# nrf54l15_application register map
Vendor: Nordic Semiconductor; Series: nrf54l; File version: 1
CPU: CM33 r0p4, little endian, MPU, FPU, 3 interrupt priority bits, 270 interrupts, 4 SAU regions
Registers are 32-bit, read-write, reset 0x0 unless marked. A register's access mark holds for its fields unless they carry their own. Offsets are from the block's base; [hi:lo] are bit positions; {n}, {i} and the like mark numbered series; 'fields as' and 'values as' point back to an identical list.

## GLOBAL_TEMP_NS — Temperature Sensor 0
Base 0x400D7000
Same registers: GLOBAL_TEMP_S 0x500D7000
0x00 TASKS_START wo — Start temperature measurement
  [0] TASKS_START
    1=Trigger task
0x04 TASKS_STOP wo — Stop temperature measurement
  [0] TASKS_STOP
    1=Trigger task
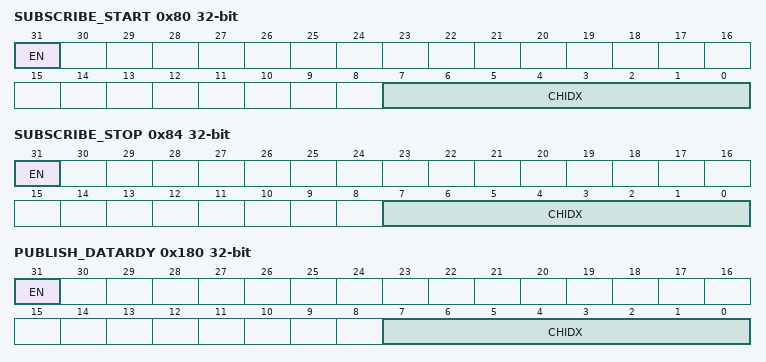
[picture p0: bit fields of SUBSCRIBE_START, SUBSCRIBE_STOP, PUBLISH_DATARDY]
0x80 SUBSCRIBE_START — Subscribe configuration for task START
  [31] EN
    0=Disabled (Disable subscription); 1=Enabled (Enable subscription)
  [7:0] CHIDX — DPPI channel that task START will subscribe to
0x84 SUBSCRIBE_STOP — Subscribe configuration for task STOP
  [31] EN
    values as SUBSCRIBE_START.EN
  [7:0] CHIDX — DPPI channel that task STOP will subscribe to
0x100 EVENTS_DATARDY — Temperature measurement complete, data ready
  [0] EVENTS_DATARDY
    0=NotGenerated (Event not generated); 1=Generated (Event generated)
0x180 PUBLISH_DATARDY — Publish configuration for event DATARDY
  [31] EN
    0=Disabled (Disable publishing); 1=Enabled (Enable publishing)
  [7:0] CHIDX — DPPI channel that event DATARDY will publish to
0x304 INTENSET — Enable interrupt
  [0] DATARDY write-1-sets — Write '1' to enable interrupt for event DATARDY
    on read: 0=Disabled (Read: Disabled); 1=Enabled (Read: Enabled) | on write: 1=Set (Enable)
0x308 INTENCLR — Disable interrupt
  [0] DATARDY write-1-clears — Write '1' to disable interrupt for event DATARDY
    on read: 0=Disabled (Read: Disabled); 1=Enabled (Read: Enabled) | on write: 1=Clear (Disable)
0x508 TEMP ro — Temperature in degC (0.25deg steps)
0x520 A0 reset 0x38C — Slope of 1st piece wise linear function
  [11:0] A0
0x524 A1 reset 0x3B3 — Slope of 2nd piece wise linear function
  [11:0] A1
0x528 A2 reset 0x3FA — Slope of 3rd piece wise linear function
  [11:0] A2
0x52C A3 reset 0x451 — Slope of 4th piece wise linear function
  [11:0] A3
0x530 A4 reset 0x4AA — Slope of 5th piece wise linear function
  [11:0] A4
0x534 A5 reset 0x539 — Slope of 6th piece wise linear function
  [11:0] A5
0x538 A6 reset 0x578 — Slope of 7th piece wise linear function
  [11:0] A6
0x540 B0 reset 0x37 — y-intercept of 1st piece wise linear function
  [11:0] B0
0x544 B1 reset 0x11 — y-intercept of 2nd piece wise linear function
  [11:0] B1
0x548 B2 reset 0x5 — y-intercept of 3rd piece wise linear function
  [11:0] B2
0x54C B3 reset 0x2B — y-intercept of 4th piece wise linear function
  [11:0] B3
0x550 B4 reset 0x8F — y-intercept of 5th piece wise linear function
  [11:0] B4
0x554 B5 reset 0x15D — y-intercept of 6th piece wise linear function
  [11:0] B5
0x558 B6 reset 0x1C0 — y-intercept of 7th piece wise linear function
  [11:0] B6
0x560 T0 reset 0xE5 — End point of 1st piece wise linear function
  [7:0] T0
0x564 T1 reset 0xFB — End point of 2nd piece wise linear function
  [7:0] T1
0x568 T2 reset 0x10 — End point of 3rd piece wise linear function
  [7:0] T2
0x56C T3 reset 0x2B — End point of 4th piece wise linear function
  [7:0] T3
0x570 T4 reset 0x41 — End point of 5th piece wise linear function
  [7:0] T4
0x574 T5 reset 0x50 — End point of 6th piece wise linear function
  [7:0] T5

## GLOBAL_POWER_NS — Power control 0
Base 0x4010E000; alternate view of GLOBAL_CLOCK_NS
Same registers: GLOBAL_POWER_S 0x5010E000 (alternate view of GLOBAL_CLOCK_S)
0x30 TASKS_CONSTLAT wo — Enable Constant Latency mode
  [0] TASKS_CONSTLAT
    1=Trigger task
0x34 TASKS_LOWPWR wo — Enable Low-power mode (variable latency)
  [0] TASKS_LOWPWR
    1=Trigger task
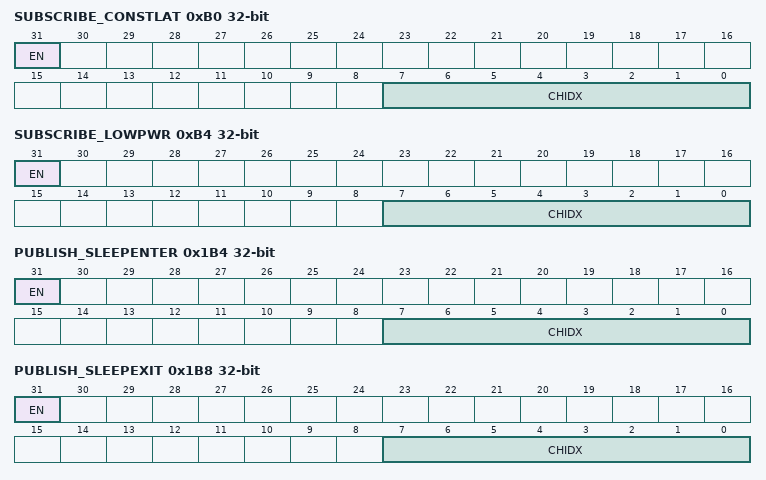
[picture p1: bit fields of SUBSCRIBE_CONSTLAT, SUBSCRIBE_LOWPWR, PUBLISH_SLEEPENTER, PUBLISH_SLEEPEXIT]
0xB0 SUBSCRIBE_CONSTLAT — Subscribe configuration for task CONSTLAT
  [31] EN
    0=Disabled (Disable subscription); 1=Enabled (Enable subscription)
  [7:0] CHIDX — DPPI channel that task CONSTLAT will subscribe to
0xB4 SUBSCRIBE_LOWPWR — Subscribe configuration for task LOWPWR
  [31] EN
    values as SUBSCRIBE_CONSTLAT.EN
  [7:0] CHIDX — DPPI channel that task LOWPWR will subscribe to
0x130 EVENTS_POFWARN — Power failure warning
  [0] EVENTS_POFWARN
    0=NotGenerated (Event not generated); 1=Generated (Event generated)
0x134 EVENTS_SLEEPENTER — CPU entered WFI/WFE sleep
  [0] EVENTS_SLEEPENTER
    values as EVENTS_POFWARN.EVENTS_POFWARN
0x138 EVENTS_SLEEPEXIT — CPU exited WFI/WFE sleep
  [0] EVENTS_SLEEPEXIT
    values as EVENTS_POFWARN.EVENTS_POFWARN
0x1B4 PUBLISH_SLEEPENTER — Publish configuration for event SLEEPENTER
  [31] EN
    0=Disabled (Disable publishing); 1=Enabled (Enable publishing)
  [7:0] CHIDX — DPPI channel that event SLEEPENTER will publish to
0x1B8 PUBLISH_SLEEPEXIT — Publish configuration for event SLEEPEXIT
  [31] EN
    values as PUBLISH_SLEEPENTER.EN
  [7:0] CHIDX — DPPI channel that event SLEEPEXIT will publish to
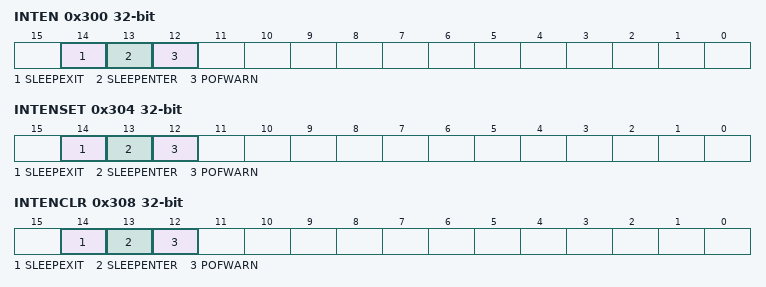
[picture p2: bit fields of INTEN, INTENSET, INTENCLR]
0x300 INTEN — Enable or disable interrupt
  [all] fields
    0=Disabled; 1=Enabled
  [14] SLEEPEXIT — Enable or disable interrupt for event SLEEPEXIT
  [13] SLEEPENTER — Enable or disable interrupt for event SLEEPENTER
  [12] POFWARN — Enable or disable interrupt for event POFWARN
0x304 INTENSET — Enable interrupt
  [all] fields
    on read: 0=Disabled (Read: Disabled); 1=Enabled (Read: Enabled) | on write: 1=Set (Enable)
  [14] SLEEPEXIT write-1-sets — Write '1' to enable interrupt for event SLEEPEXIT
  [13] SLEEPENTER write-1-sets — Write '1' to enable interrupt for event SLEEPENTER
  [12] POFWARN write-1-sets — Write '1' to enable interrupt for event POFWARN
0x308 INTENCLR — Disable interrupt
  [all] fields
    on read: 0=Disabled (Read: Disabled); 1=Enabled (Read: Enabled) | on write: 1=Clear (Disable)
  [14] SLEEPEXIT write-1-clears — Write '1' to disable interrupt for event SLEEPEXIT
  [13] SLEEPENTER write-1-clears — Write '1' to disable interrupt for event SLEEPENTER
  [12] POFWARN write-1-clears — Write '1' to disable interrupt for event POFWARN
{0x500+4i} GPREGRET[{i}] (i=0..1) — Description collection: General purpose retention register
  [7:0] GPREGRET — General purpose retention register
0x520 CONSTLATSTAT ro — Status of constant latency
  [0] STATUS
    0=Disable (Constant latency disabled); 1=Enable (Constant latency enabled)
